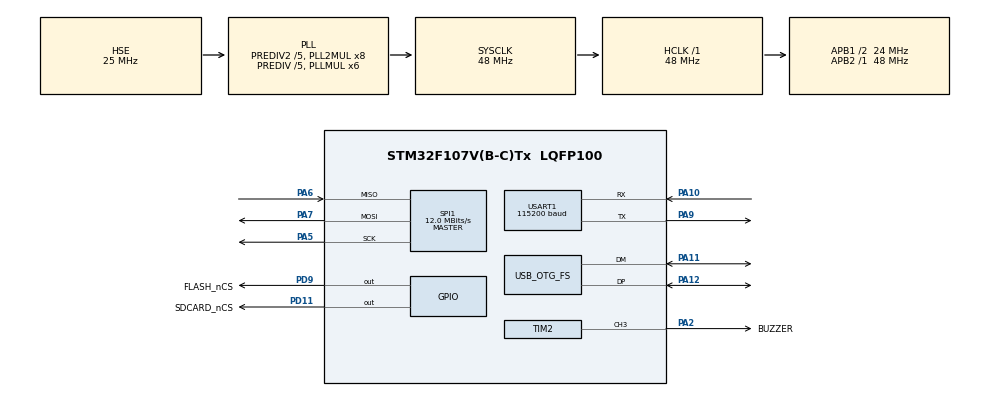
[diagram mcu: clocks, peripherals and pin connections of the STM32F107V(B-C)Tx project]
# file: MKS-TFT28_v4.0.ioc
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FATFS._CODE_PAGE=850
FATFS._USE_LFN=2
FATFS._VOLUMES=3
FREERTOS.Tasks01=defaultTask,0,128,StartDefaultTask,Default,NULL
Mcu.Family=STM32F1
Mcu.Name=STM32F107V(B-C)Tx
Mcu.Package=LQFP100
NVIC.OTG_FS_IRQn=true\:5\:0\:false\:true\:true\:2\:true\:false\:true
NVIC.PriorityGroup=NVIC_PRIORITYGROUP_4
NVIC.TIM1_UP_IRQn=true\:0\:0\:false\:false\:true\:false\:false\:true
NVIC.TimeBase=TIM1_UP_IRQn
NVIC.TimeBaseIP=TIM1
NVIC.USART1_IRQn=true\:5\:0\:false\:true\:true\:1\:true\:true\:true
OSC_IN.Mode=HSE-External-Oscillator
OSC_IN.Signal=RCC_OSC_IN
OSC_OUT.Mode=HSE-External-Oscillator
OSC_OUT.Signal=RCC_OSC_OUT
PA10.Mode=Asynchronous
PA10.Signal=USART1_RX
PA11.Mode=Host_Only
PA11.Signal=USB_OTG_FS_DM
PA12.Mode=Host_Only
PA12.Signal=USB_OTG_FS_DP
PA13.Mode=Serial_Wire
PA13.Signal=SYS_JTMS-SWDIO
PA14.Mode=Serial_Wire
PA14.Signal=SYS_JTCK-SWCLK
PA2.GPIO_Label=BUZZER
PA2.Signal=S_TIM2_CH3
PA5.Mode=Full_Duplex_Master
PA5.Signal=SPI1_SCK
PA6.Mode=Full_Duplex_Master
PA6.Signal=SPI1_MISO
PA7.Mode=Full_Duplex_Master
PA7.Signal=SPI1_MOSI
PA9.Mode=Asynchronous
PA9.Signal=USART1_TX
PD11.GPIO_Label=SDCARD_nCS
PD11.Signal=GPIO_Output
PD9.GPIO_Label=FLASH_nCS
PD9.Signal=GPIO_Output
ProjectManager.HeapSize=0x400
ProjectManager.StackSize=0x800
ProjectManager.TargetToolchain=TrueSTUDIO
RCC.AHBFreq_Value=48000000
RCC.APB1CLKDivider=RCC_HCLK_DIV2
RCC.APB1Freq_Value=24000000
RCC.APB1TimFreq_Value=48000000
RCC.APB2Freq_Value=48000000
RCC.APB2TimFreq_Value=48000000
RCC.HCLKFreq_Value=48000000
RCC.HSEDivPLL=RCC_HSE_PREDIV_DIV5
RCC.HSE_VALUE=25000000
RCC.PLLMUL=RCC_PLL_MUL6
RCC.PLLSourceVirtual=RCC_PLLSOURCE_HSE
RCC.Prediv1Source=RCC_PREDIV1_SOURCE_PLL2
RCC.Prediv2=RCC_HSE_PREDIV2_DIV5
RCC.SYSCLKFreq_VALUE=48000000
RCC.SYSCLKSource=RCC_SYSCLKSOURCE_PLLCLK
RCC.USBFreq_Value=48000000
RCC.USBPrescaler=RCC_USBCLKSOURCE_PLL_DIV2
SH.S_TIM2_CH3.0=TIM2_CH3,Output Compare3 CH3
SPI1.BaudRatePrescaler=SPI_BAUDRATEPRESCALER_4
SPI1.CalculateBaudRate=12.0 MBits/s
SPI1.Direction=SPI_DIRECTION_2LINES
SPI1.Mode=SPI_MODE_MASTER
SPI1.VirtualType=VM_MASTER
TIM2.Channel-Output\ Compare3\ CH3=TIM_CHANNEL_3
TIM2.OCMode_3=TIM_OCMODE_TOGGLE
TIM2.Period=14399
TIM2.Pulse-Output\ Compare3\ CH3=1
TIM2.TIM_MasterOutputTrigger=TIM_TRGO_OC3REF
USART1.BaudRate=115200
USART1.VirtualMode=VM_ASYNC
USB_HOST.USBH_DEBUG_LEVEL=3
USB_HOST.USBH_HandleTypeDef=hUsbHostFS
USB_HOST.USBH_USE_OS-MSC_FS=0
USB_HOST.VirtualModeFS=Msc
USB_OTG_FS.Sof_enable=ENABLE
USB_OTG_FS.VirtualMode=Host_Only
USB_OTG_FS.speed=HCD_SPEED_FULL
VP_FATFS_VS_Generic.Mode=User_defined
VP_FATFS_VS_USB.Mode=USB
VP_FREERTOS_VS_CMSIS_V1.Mode=CMSIS_V1
VP_SYS_VS_tim1.Mode=TIM1
VP_USB_HOST_VS_USB_HOST_MSC_FS.Mode=MSC_FS
board=custom

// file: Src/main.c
/* USER CODE BEGIN Header */
/**
  ******************************************************************************
  * @file           : main.c
  * @brief          : Main program body
  ******************************************************************************
  * @attention
  *
  * <h2><center>&copy; Copyright (c) 2019 STMicroelectronics.
  * All rights reserved.</center></h2>
  *
  * This software component is licensed by ST under Ultimate Liberty license
  * SLA0044, the "License"; You may not use this file except in compliance with
  * the License. You may obtain a copy of the License at:
  *                             www.st.com/SLA0044
  *
  ******************************************************************************
  */
/* USER CODE END Header */

#include "main.h"
#include "cmsis_os.h"
#include "fatfs.h"
#include "spi.h"
#include "tim.h"
#include "usart.h"
#include "usb_host.h"
#include "gpio.h"

/* USER CODE BEGIN Includes */
//#include "boot_conf.h"
#include <stdio.h>
#include <string.h>
/* USER CODE END Includes */

/* USER CODE BEGIN PD */

static void ShortBeep();

/* USER CODE END PD */

void SystemClock_Config(void);
void MX_FREERTOS_Init(void);
static void MX_NVIC_Init(void);
/* USER CODE BEGIN PFP */

void HAL_TIM_MspPostInit(TIM_HandleTypeDef *htim);
//FRESULT Explore_Disk(char *path, uint8_t recu_level);
//static FIL MyFile;

/* USER CODE END PFP */

/* USER CODE BEGIN 0 */
inline void moveVectorTable(uint32_t Offset)
{
    // __disable_irq();
    SCB->VTOR = FLASH_BASE | Offset;
}

//extern USBH_HandleTypeDef hUsbHostFS;

/* USER CODE END 0 */

int main(void)
{
  /* USER CODE BEGIN 1 */
  //FRESULT res;
  /* USER CODE END 1 */

  /* MCU Configuration--------------------------------------------------------*/

  /* Reset of all peripherals, Initializes the Flash interface and the Systick. */
  HAL_Init();

  /* Configure the system clock */
  SystemClock_Config();

  /* Initialize all configured peripherals */
  MX_GPIO_Init();
  MX_TIM2_Init();
  MX_USART1_UART_Init();
  MX_SPI1_Init();

  /* Initialize interrupts */
  MX_NVIC_Init();
  /* USER CODE BEGIN 2 */
  printf("\n\rBooting\n\r");
  //MX_USB_HOST_Process();

  ShortBeep();
  /*
  printf("\n\rMounting Filesystem...\n\r");
  res = f_mount(&USBHFatFS, (TCHAR const*)USBHPath, 0);

  if (res != FR_OK)
  {
	  printf("Failed to open %s, error %d\n\r", (TCHAR const*)USBHPath, res);
  } else {
	  printf("Mounted %s with exit code %d\n\r", (TCHAR const*)USBHPath, res);
	  f_open(&MyFile, "0:/STM32.TXT", FA_CREATE_ALWAYS | FA_WRITE);
	  if (res != FR_OK)
	  {
		  printf("Failed to open file with result : %d\n\r", res);
	  } else {
		  //f_write(&MyFile, wtext, sizeof(wtext), (void *)&byteswritten);
	  }
  }*/
  /*
  if (FR_OK == f_mount(&sdFileSystem, SPISD_Path, 1) && FR_OK == flash("0:/firmware.bin"))
  {
      f_mount(NULL, SPISD_Path, 1);
      ShortBeep();
      HAL_SPI_MspDeInit(&hspi1);
      HAL_TIM_Base_MspDeInit(&htim2);

      __HAL_RCC_GPIOA_CLK_DISABLE();
      __HAL_RCC_GPIOB_CLK_DISABLE();
      __HAL_RCC_GPIOC_CLK_DISABLE();
      __HAL_RCC_GPIOD_CLK_DISABLE();
      __HAL_RCC_GPIOE_CLK_DISABLE();

      HAL_DeInit();

      // Disabling SysTick interrupt
      SysTick->CTRL = 0;
      moveVectorTable(MAIN_PR_OFFSET);
      // Setting initial value to stack pointer
      __set_MSP(*mcuFirstPageAddr);
      // booting really

      Callable resetHandler = (Callable) (*(mcuFirstPageAddr + 1) );
      resetHandler();
  }
 */
  /* USER CODE END 2 */

  /* Call init function for freertos objects (in freertos.c) */
  MX_FREERTOS_Init();

  /* Start scheduler */
  osKernelStart();

  /* We should never get here as control is now taken by the scheduler */

  /* Infinite loop */
  /* USER CODE BEGIN WHILE */
  while (1)
  {
    //ShortBeep();
    //HAL_Delay(5000);
    //printf("beep\n\r");
    /* USER CODE END WHILE */

  }
}

void SystemClock_Config(void)
{
  RCC_OscInitTypeDef RCC_OscInitStruct = {0};
  RCC_ClkInitTypeDef RCC_ClkInitStruct = {0};
  RCC_PeriphCLKInitTypeDef PeriphClkInit = {0};

  /** Initializes the CPU, AHB and APB busses clocks
  */
  RCC_OscInitStruct.OscillatorType = RCC_OSCILLATORTYPE_HSE;
  RCC_OscInitStruct.HSEState = RCC_HSE_ON;
  RCC_OscInitStruct.HSEPredivValue = RCC_HSE_PREDIV_DIV5;
  RCC_OscInitStruct.HSIState = RCC_HSI_ON;
  RCC_OscInitStruct.Prediv1Source = RCC_PREDIV1_SOURCE_PLL2;
  RCC_OscInitStruct.PLL.PLLState = RCC_PLL_ON;
  RCC_OscInitStruct.PLL.PLLSource = RCC_PLLSOURCE_HSE;
  RCC_OscInitStruct.PLL.PLLMUL = RCC_PLL_MUL6;
  RCC_OscInitStruct.PLL2.PLL2State = RCC_PLL2_ON;
  RCC_OscInitStruct.PLL2.PLL2MUL = RCC_PLL2_MUL8;
  RCC_OscInitStruct.PLL2.HSEPrediv2Value = RCC_HSE_PREDIV2_DIV5;
  if (HAL_RCC_OscConfig(&RCC_OscInitStruct) != HAL_OK)
  {
    Error_Handler();
  }
  /** Initializes the CPU, AHB and APB busses clocks
  */
  RCC_ClkInitStruct.ClockType = RCC_CLOCKTYPE_HCLK|RCC_CLOCKTYPE_SYSCLK
                              |RCC_CLOCKTYPE_PCLK1|RCC_CLOCKTYPE_PCLK2;
  RCC_ClkInitStruct.SYSCLKSource = RCC_SYSCLKSOURCE_PLLCLK;
  RCC_ClkInitStruct.AHBCLKDivider = RCC_SYSCLK_DIV1;
  RCC_ClkInitStruct.APB1CLKDivider = RCC_HCLK_DIV2;
  RCC_ClkInitStruct.APB2CLKDivider = RCC_HCLK_DIV1;

  if (HAL_RCC_ClockConfig(&RCC_ClkInitStruct, FLASH_LATENCY_1) != HAL_OK)
  {
    Error_Handler();
  }
  PeriphClkInit.PeriphClockSelection = RCC_PERIPHCLK_USB;
  PeriphClkInit.UsbClockSelection = RCC_USBCLKSOURCE_PLL_DIV2;
  if (HAL_RCCEx_PeriphCLKConfig(&PeriphClkInit) != HAL_OK)
  {
    Error_Handler();
  }
  /** Configure the Systick interrupt time
  */
  __HAL_RCC_PLLI2S_ENABLE();
}

/**
  * @brief NVIC Configuration.
  * @retval None
  */
static void MX_NVIC_Init(void)
{
  /* USART1_IRQn interrupt configuration */
  HAL_NVIC_SetPriority(USART1_IRQn, 5, 0);
  HAL_NVIC_EnableIRQ(USART1_IRQn);
  /* OTG_FS_IRQn interrupt configuration */
  HAL_NVIC_SetPriority(OTG_FS_IRQn, 5, 0);
  HAL_NVIC_EnableIRQ(OTG_FS_IRQn);
}

/* USER CODE BEGIN 4 */
void ShortBeep()
{
	HAL_TIM_OC_Start_IT(&htim2, TIM_CHANNEL_3);
	HAL_Delay(40);
	HAL_TIM_OC_Stop_IT(&htim2, TIM_CHANNEL_3);
}
/* USER CODE END 4 */

void HAL_TIM_PeriodElapsedCallback(TIM_HandleTypeDef *htim)
{
  if (htim->Instance == TIM1) {
    HAL_IncTick();
  }
}

void Error_Handler(void)
{
  /* USER CODE BEGIN Error_Handler_Debug */
  /* User can add his own implementation to report the HAL error return state */
  printf("ERROR\n\r");
  /* USER CODE END Error_Handler_Debug */
}

/************************ (C) COPYRIGHT STMicroelectronics *****END OF FILE****/

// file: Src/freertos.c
/* USER CODE BEGIN Header */
/**
  ******************************************************************************
  * File Name          : freertos.c
  * Description        : Code for freertos applications
  ******************************************************************************
  * @attention
  *
  * <h2><center>&copy; Copyright (c) 2019 STMicroelectronics.
  * All rights reserved.</center></h2>
  *
  * This software component is licensed by ST under Ultimate Liberty license
  * SLA0044, the "License"; You may not use this file except in compliance with
  * the License. You may obtain a copy of the License at:
  *                             www.st.com/SLA0044
  *
  ******************************************************************************
  */
/* USER CODE END Header */

#include "FreeRTOS.h"
#include "task.h"
#include "main.h"
#include "cmsis_os.h"

osThreadId defaultTaskHandle;

void StartDefaultTask(void const * argument);

extern void MX_USB_HOST_Init(void);
extern void MX_FATFS_Init(void);
void MX_FREERTOS_Init(void); /* (MISRA C 2004 rule 8.1) */

void MX_FREERTOS_Init(void) {

  /* Create the thread(s) */
  /* definition and creation of defaultTask */
  osThreadDef(defaultTask, StartDefaultTask, osPriorityNormal, 0, 128);
  defaultTaskHandle = osThreadCreate(osThread(defaultTask), NULL);

}

void StartDefaultTask(void const * argument)
{

  /* init code for USB_HOST */
  MX_USB_HOST_Init();

  /* init code for FATFS */
  MX_FATFS_Init();

  for(;;)
  {
    osDelay(1);
  }
}

/************************ (C) COPYRIGHT STMicroelectronics *****END OF FILE****/
